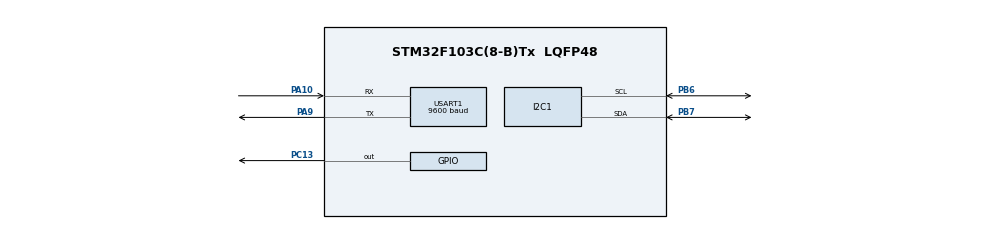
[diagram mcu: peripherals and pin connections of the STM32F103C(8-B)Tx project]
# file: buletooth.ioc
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FREERTOS.Queues01=MainQueue,16,uint8_t,0,Dynamic,NULL,NULL;BlueQueue,16,uint8_t,0,Dynamic,NULL,NULL;ScreenQueue,16,uint8_t,0,Dynamic,NULL,NULL
FREERTOS.Tasks01=bluetoohTask,24,128,BlueTask,Default,NULL,Dynamic,NULL,NULL;mainTask,40,128,MainTask,Default,NULL,Dynamic,NULL,NULL;screenTask,8,128,ScreenTask,Default,NULL,Dynamic,NULL,NULL
Mcu.Family=STM32F1
Mcu.Name=STM32F103C(8-B)Tx
Mcu.Package=LQFP48
NVIC.PriorityGroup=NVIC_PRIORITYGROUP_4
NVIC.USART1_IRQn=true\:5\:0\:false\:false\:true\:true\:true\:true\:true
PA10.Mode=Asynchronous
PA10.Signal=USART1_RX
PA13.Mode=Serial_Wire
PA13.Signal=SYS_JTMS-SWDIO
PA14.Mode=Serial_Wire
PA14.Signal=SYS_JTCK-SWCLK
PA9.Mode=Asynchronous
PA9.Signal=USART1_TX
PB6.Mode=I2C
PB6.Signal=I2C1_SCL
PB7.Mode=I2C
PB7.Signal=I2C1_SDA
PC13-TAMPER-RTC.Signal=GPIO_Output
ProjectManager.HeapSize=0x200
ProjectManager.StackSize=0x400
ProjectManager.TargetToolchain=STM32CubeIDE
RCC.APB1Freq_Value=8000000
RCC.APB2Freq_Value=8000000
USART1.BaudRate=9600
USART1.VirtualMode=VM_ASYNC
VP_FREERTOS_VS_CMSIS_V2.Mode=CMSIS_V2
board=custom

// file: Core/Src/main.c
/* USER CODE BEGIN Header */
/**
  ******************************************************************************
  * @file           : main.c
  * @brief          : Main program body
  ******************************************************************************
  * @attention
  *
  * Copyright (c) 2024 STMicroelectronics.
  * All rights reserved.
  *
  * This software is licensed under terms that can be found in the LICENSE file
  * in the root directory of this software component.
  * If no LICENSE file comes with this software, it is provided AS-IS.
  *
  ******************************************************************************
  */
/* USER CODE END Header */
#include "main.h"
#include "cmsis_os.h"
#include"oled.h"
#include "screentask.h"
#include"maintask.h"
#include"bluetask.h"
#include"config.h"

uint8_t rx_data;

I2C_HandleTypeDef hi2c1;

UART_HandleTypeDef huart1;

/* Definitions for bluetoohTask */
osThreadId_t bluetoohTaskHandle;
const osThreadAttr_t bluetoohTask_attributes = {
  .name = "bluetoohTask",
  .stack_size = 128 * 4,
  .priority = (osPriority_t) osPriorityNormal,
};
/* Definitions for mainTask */
osThreadId_t mainTaskHandle;
const osThreadAttr_t mainTask_attributes = {
  .name = "mainTask",
  .stack_size = 128 * 4,
  .priority = (osPriority_t) osPriorityHigh,
};
/* Definitions for screenTask */
osThreadId_t screenTaskHandle;
const osThreadAttr_t screenTask_attributes = {
  .name = "screenTask",
  .stack_size = 128 * 4,
  .priority = (osPriority_t) osPriorityLow,
};
/* Definitions for MainQueue */
osMessageQueueId_t MainQueueHandle;
const osMessageQueueAttr_t MainQueue_attributes = {
  .name = "MainQueue"
};
/* Definitions for BlueQueue */
osMessageQueueId_t BlueQueueHandle;
const osMessageQueueAttr_t BlueQueue_attributes = {
  .name = "BlueQueue"
};
/* Definitions for ScreenQueue */
osMessageQueueId_t ScreenQueueHandle;
const osMessageQueueAttr_t ScreenQueue_attributes = {
  .name = "ScreenQueue"
};

void SystemClock_Config(void);
static void MX_GPIO_Init(void);
static void MX_I2C1_Init(void);
static void MX_USART1_UART_Init(void);

void HAL_UART_RxCpltCallback(UART_HandleTypeDef *huart){
    if(huart->Instance == USART1){
//    	xQueueSendxQueueSendFromISR()
    	HAL_GPIO_TogglePin (GPIOC, GPIO_PIN_13);
    	osMessageQueuePut(ScreenQueueHandle, &rx_data, 0,0);
        HAL_UART_Receive_IT(&huart1, &rx_data, 1);
    }
}

int main(void)
{

  HAL_Init();

  SystemClock_Config();

  MX_GPIO_Init();
  MX_I2C1_Init();
  MX_USART1_UART_Init();
  /* USER CODE BEGIN 2 */
  initOLED(&hi2c1);
  /* USER CODE END 2 */

  /* Init scheduler */
  osKernelInitialize();
  HAL_UART_Receive_IT(&huart1, &rx_data, 1);

  MainQueueHandle = osMessageQueueNew (16, sizeof(uint8_t), &MainQueue_attributes);

  /* creation of BlueQueue */
  BlueQueueHandle = osMessageQueueNew (16, sizeof(uint8_t), &BlueQueue_attributes);

  /* creation of ScreenQueue */
  ScreenQueueHandle = osMessageQueueNew (16, sizeof(uint8_t), &ScreenQueue_attributes);

  bluetoohTaskHandle = osThreadNew(BlueTask, NULL, &bluetoohTask_attributes);

  /* creation of mainTask */
  mainTaskHandle = osThreadNew(MainTask, NULL, &mainTask_attributes);

  /* creation of screenTask */
  screenTaskHandle = osThreadNew(ScreenTask, NULL, &screenTask_attributes);

  /* Start scheduler */
  osKernelStart();

  while (1)
  {

  }
}

void SystemClock_Config(void)
{
  RCC_OscInitTypeDef RCC_OscInitStruct = {0};
  RCC_ClkInitTypeDef RCC_ClkInitStruct = {0};

  /** Initializes the RCC Oscillators according to the specified parameters
  * in the RCC_OscInitTypeDef structure.
  */
  RCC_OscInitStruct.OscillatorType = RCC_OSCILLATORTYPE_HSI;
  RCC_OscInitStruct.HSIState = RCC_HSI_ON;
  RCC_OscInitStruct.HSICalibrationValue = RCC_HSICALIBRATION_DEFAULT;
  RCC_OscInitStruct.PLL.PLLState = RCC_PLL_NONE;
  if (HAL_RCC_OscConfig(&RCC_OscInitStruct) != HAL_OK)
  {
    Error_Handler();
  }

  /** Initializes the CPU, AHB and APB buses clocks
  */
  RCC_ClkInitStruct.ClockType = RCC_CLOCKTYPE_HCLK|RCC_CLOCKTYPE_SYSCLK
                              |RCC_CLOCKTYPE_PCLK1|RCC_CLOCKTYPE_PCLK2;
  RCC_ClkInitStruct.SYSCLKSource = RCC_SYSCLKSOURCE_HSI;
  RCC_ClkInitStruct.AHBCLKDivider = RCC_SYSCLK_DIV1;
  RCC_ClkInitStruct.APB1CLKDivider = RCC_HCLK_DIV1;
  RCC_ClkInitStruct.APB2CLKDivider = RCC_HCLK_DIV1;

  if (HAL_RCC_ClockConfig(&RCC_ClkInitStruct, FLASH_LATENCY_0) != HAL_OK)
  {
    Error_Handler();
  }
}

static void MX_I2C1_Init(void)
{

  hi2c1.Instance = I2C1;
  hi2c1.Init.ClockSpeed = 100000;
  hi2c1.Init.DutyCycle = I2C_DUTYCYCLE_2;
  hi2c1.Init.OwnAddress1 = 0;
  hi2c1.Init.AddressingMode = I2C_ADDRESSINGMODE_7BIT;
  hi2c1.Init.DualAddressMode = I2C_DUALADDRESS_DISABLE;
  hi2c1.Init.OwnAddress2 = 0;
  hi2c1.Init.GeneralCallMode = I2C_GENERALCALL_DISABLE;
  hi2c1.Init.NoStretchMode = I2C_NOSTRETCH_DISABLE;
  if (HAL_I2C_Init(&hi2c1) != HAL_OK)
  {
    Error_Handler();
  }

}

static void MX_USART1_UART_Init(void)
{

  huart1.Instance = USART1;
  huart1.Init.BaudRate = 9600;
  huart1.Init.WordLength = UART_WORDLENGTH_8B;
  huart1.Init.StopBits = UART_STOPBITS_1;
  huart1.Init.Parity = UART_PARITY_NONE;
  huart1.Init.Mode = UART_MODE_TX_RX;
  huart1.Init.HwFlowCtl = UART_HWCONTROL_NONE;
  huart1.Init.OverSampling = UART_OVERSAMPLING_16;
  if (HAL_UART_Init(&huart1) != HAL_OK)
  {
    Error_Handler();
  }

}

static void MX_GPIO_Init(void)
{
  GPIO_InitTypeDef GPIO_InitStruct = {0};

  /* GPIO Ports Clock Enable */
  __HAL_RCC_GPIOC_CLK_ENABLE();
  __HAL_RCC_GPIOA_CLK_ENABLE();
  __HAL_RCC_GPIOB_CLK_ENABLE();

  /*Configure GPIO pin Output Level */
  HAL_GPIO_WritePin(INDICATOR_LED_PORT, INDICATOR_LED_PIN, GPIO_PIN_RESET);

  /*Configure GPIO pin : PC13 */
  GPIO_InitStruct.Pin = INDICATOR_LED_PIN;
  GPIO_InitStruct.Mode = GPIO_MODE_OUTPUT_PP;
  GPIO_InitStruct.Pull = GPIO_NOPULL;
  GPIO_InitStruct.Speed = GPIO_SPEED_FREQ_LOW;
  HAL_GPIO_Init(INDICATOR_LED_PORT, &GPIO_InitStruct);

}

void Error_Handler(void)
{
  __disable_irq();
  while (1)
  {
  }
}
